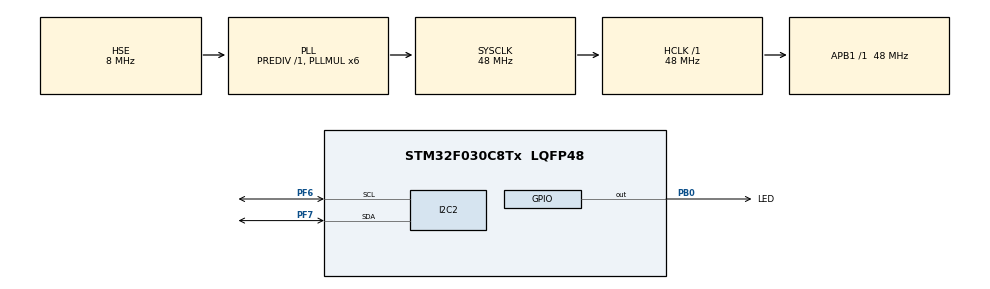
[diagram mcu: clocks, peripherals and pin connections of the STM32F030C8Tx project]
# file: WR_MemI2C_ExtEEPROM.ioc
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I2C2.Timing=0x20303E5D
Mcu.Family=STM32F0
Mcu.Name=STM32F030C8Tx
Mcu.Package=LQFP48
PA13.Mode=Serial_Wire
PA13.Signal=SYS_SWDIO
PA14.Mode=Serial_Wire
PA14.Signal=SYS_SWCLK
PB0.GPIO_Label=LED
PB0.PinState=GPIO_PIN_SET
PB0.Signal=GPIO_Output
PF0-OSC_IN.Mode=HSE-External-Oscillator
PF0-OSC_IN.Signal=RCC_OSC_IN
PF1-OSC_OUT.Mode=HSE-External-Oscillator
PF1-OSC_OUT.Signal=RCC_OSC_OUT
PF6.Mode=I2C
PF6.Signal=I2C2_SCL
PF7.Mode=I2C
PF7.Signal=I2C2_SDA
ProjectManager.HeapSize=0x200
ProjectManager.StackSize=0x400
ProjectManager.TargetToolchain=MDK-ARM V5.32
RCC.AHBFreq_Value=48000000
RCC.APB1Freq_Value=48000000
RCC.APB1TimFreq_Value=48000000
RCC.HCLKFreq_Value=48000000
RCC.PLLMUL=RCC_PLL_MUL6
RCC.PLLSourceVirtual=RCC_PLLSOURCE_HSE
RCC.SYSCLKFreq_VALUE=48000000
RCC.SYSCLKSource=RCC_SYSCLKSOURCE_PLLCLK
board=custom

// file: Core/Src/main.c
/* USER CODE BEGIN Header */
/**
  ******************************************************************************
  * @file           : main.c
  * @brief          : Main program body
  ******************************************************************************
  * @attention
  *
  * Copyright (c) 2024 STMicroelectronics.
  * All rights reserved.
  *
  * This software is licensed under terms that can be found in the LICENSE file
  * in the root directory of this software component.
  * If no LICENSE file comes with this software, it is provided AS-IS.
  *
  ******************************************************************************
  */
/* USER CODE END Header */
#include "main.h"
#include "i2c.h"
#include "gpio.h"

/* USER CODE BEGIN Includes */

#define DeviceAddress 0x50

/* USER CODE END Includes */

/* USER CODE BEGIN PV */

uint16_t myAddress = 0;
uint8_t myData_tx = 0;
uint8_t myData_rx = 0;

uint8_t FLAG_ERROR = 0;

/* USER CODE END PV */

void SystemClock_Config(void);
/* USER CODE BEGIN PFP */

uint8_t Write_Read_I2CMem(I2C_HandleTypeDef *hi2c, uint8_t DevAddress, uint16_t MemAddress, uint8_t *data_tx, uint8_t *data_rx);

/* USER CODE END PFP */

int main(void)
{

  /* MCU Configuration--------------------------------------------------------*/

  /* Reset of all peripherals, Initializes the Flash interface and the Systick. */
  HAL_Init();

  /* Configure the system clock */
  SystemClock_Config();

  /* Initialize all configured peripherals */
  MX_GPIO_Init();
  MX_I2C2_Init();
  /* USER CODE BEGIN 2 */

	if(HAL_I2C_IsDeviceReady(&hi2c2, (DeviceAddress << 1), 3, 100) == HAL_OK)
	{
		myAddress = 0;
		myData_tx = 0xAA;
		FLAG_ERROR = Write_Read_I2CMem(&hi2c2, DeviceAddress, myAddress, &myData_tx, &myData_rx);

		HAL_Delay(100);

		myAddress = 100;
		myData_tx = 0x55;
		FLAG_ERROR = Write_Read_I2CMem(&hi2c2, DeviceAddress, myAddress, &myData_tx, &myData_rx);

		HAL_Delay(100);

		myAddress = 1200;
		myData_tx = 0xCC;
		FLAG_ERROR = Write_Read_I2CMem(&hi2c2, DeviceAddress, myAddress, &myData_tx, &myData_rx);
	}
	else
	{
		FLAG_ERROR = 1;
	}

  /* USER CODE END 2 */

  /* Infinite loop */
  /* USER CODE BEGIN WHILE */
  while (1)
  {
		if(FLAG_ERROR == 1)
			HAL_GPIO_TogglePin(LED_GPIO_Port, LED_Pin);

    /* USER CODE END WHILE */

  }
}

void SystemClock_Config(void)
{
  RCC_OscInitTypeDef RCC_OscInitStruct = {0};
  RCC_ClkInitTypeDef RCC_ClkInitStruct = {0};

  /** Initializes the RCC Oscillators according to the specified parameters
  * in the RCC_OscInitTypeDef structure.
  */
  RCC_OscInitStruct.OscillatorType = RCC_OSCILLATORTYPE_HSE;
  RCC_OscInitStruct.HSEState = RCC_HSE_ON;
  RCC_OscInitStruct.PLL.PLLState = RCC_PLL_ON;
  RCC_OscInitStruct.PLL.PLLSource = RCC_PLLSOURCE_HSE;
  RCC_OscInitStruct.PLL.PLLMUL = RCC_PLL_MUL6;
  RCC_OscInitStruct.PLL.PREDIV = RCC_PREDIV_DIV1;
  if (HAL_RCC_OscConfig(&RCC_OscInitStruct) != HAL_OK)
  {
    Error_Handler();
  }

  /** Initializes the CPU, AHB and APB buses clocks
  */
  RCC_ClkInitStruct.ClockType = RCC_CLOCKTYPE_HCLK|RCC_CLOCKTYPE_SYSCLK
                              |RCC_CLOCKTYPE_PCLK1;
  RCC_ClkInitStruct.SYSCLKSource = RCC_SYSCLKSOURCE_PLLCLK;
  RCC_ClkInitStruct.AHBCLKDivider = RCC_SYSCLK_DIV1;
  RCC_ClkInitStruct.APB1CLKDivider = RCC_HCLK_DIV1;

  if (HAL_RCC_ClockConfig(&RCC_ClkInitStruct, FLASH_LATENCY_1) != HAL_OK)
  {
    Error_Handler();
  }
}

/* USER CODE BEGIN 4 */

uint8_t Write_Read_I2CMem(I2C_HandleTypeDef *hi2c, uint8_t DevAddress, uint16_t MemAddress, uint8_t *data_tx, uint8_t *data_rx)
{
	uint8_t FLAG = 0;

	if(HAL_I2C_Mem_Write(hi2c, (DevAddress << 1), MemAddress, I2C_MEMADD_SIZE_16BIT, data_tx, 1, 100) == HAL_OK)
	{
		HAL_Delay(5);
		if(HAL_I2C_Mem_Read(hi2c, (DevAddress << 1), MemAddress, I2C_MEMADD_SIZE_16BIT, data_rx, 1, 100) == HAL_OK)
		{
			if(myData_rx == myData_tx)
			{
				//OK
				HAL_GPIO_WritePin(LED_GPIO_Port, LED_Pin, GPIO_PIN_RESET);
			}
			else
			{
				FLAG = 1;
			}
		}
		else
		{
			FLAG = 1;
		}
	}
	else
	{
		FLAG = 1;
	}

	return FLAG;
}
/* USER CODE END 4 */

void Error_Handler(void)
{
  __disable_irq();
  while (1)
  {
  }
}
